# 3067M register map
File version: 1.0
Registers are 32-bit, access per field, reset 0x0 unless marked. A register's access mark holds for its fields unless they carry their own. Offsets are from the block's base; [hi:lo] are bit positions; {n}, {i} and the like mark numbered series.

## TSENSOR — TSENSOR peripheral interface
Base 0x18500000
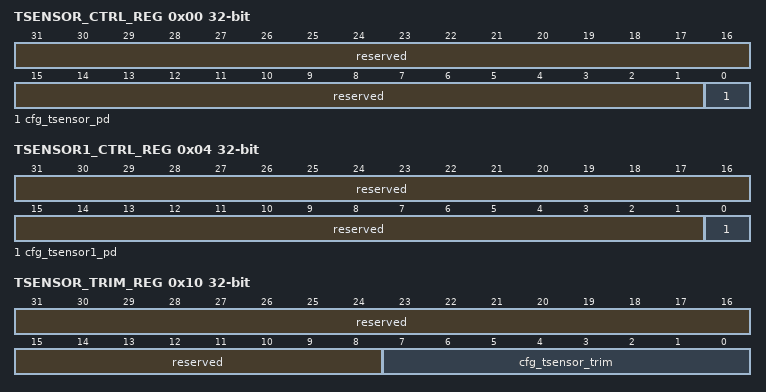
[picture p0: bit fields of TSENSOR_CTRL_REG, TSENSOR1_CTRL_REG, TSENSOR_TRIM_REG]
0x00 TSENSOR_CTRL_REG — TSENSOR控制寄存器。
  [31:1] reserved ro — 保留。
  [0] cfg_tsensor_pd rw — Tsensor0的关断信号。 0：使能Tsensor0； 1：关断Tsensor0。
0x04 TSENSOR1_CTRL_REG — TSENSOR1控制寄存器。
  [31:1] reserved ro — 保留。
  [0] cfg_tsensor1_pd rw — Tsensor1的关断信号。 0：使能Tsensor1； 1：关断Tsensor1。
0x10 TSENSOR_TRIM_REG — TSENSOR TRIM寄存器
  [31:8] reserved ro — 保留。
  [7:0] cfg_tsensor_trim rw — Tsensor0 trim信息。

## SYSCTRL0 — SYSCTRL0 peripheral interface
Base 0x10100000
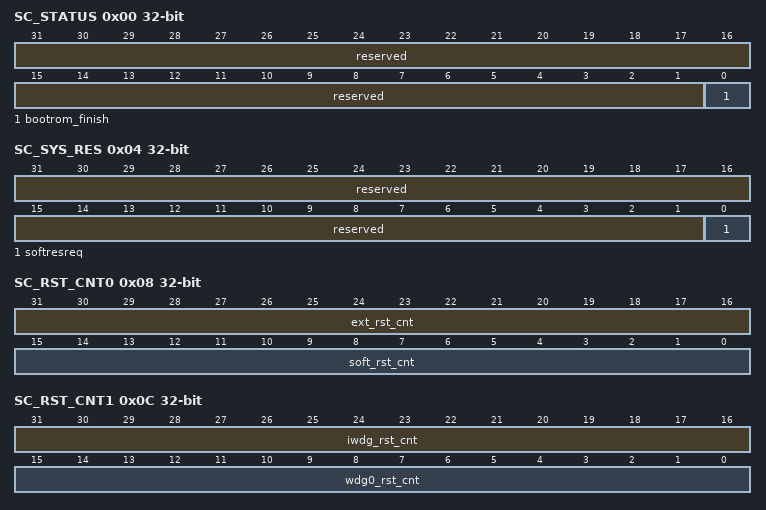
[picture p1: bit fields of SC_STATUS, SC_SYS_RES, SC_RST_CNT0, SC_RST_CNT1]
0x00 SC_STATUS access not given — SC_STATUS为系统状态寄存器。
  [31:1] reserved ro — 保留。
  [0] bootrom_finish — bootrom退出时，需将该寄存器改写为1。 注意：与OTP的bootrom_debug_enable、bootrom_hide_disable配合完成相关安全保护。
0x04 SC_SYS_RES access not given — SC_SYS_RES为系统软件复位寄存器。 该寄存器受写保护控制，由寄存器SC_LOCKEN[sc_cfg_lock]决定。只有写使能时，对此寄存器的写操作才有效。
  [31:1] reserved ro — 保留。
  [0] softresreq — 对此寄存器位域的任意写操作都会导致系统软复位。
0x08 SC_RST_CNT0 ro — SC_RST_CNT0为复位次数统计寄存器0。
  [31:16] ext_rst_cnt — RESETN管脚复位次数统计。
  [15:0] soft_rst_cnt — 软复位次数统计。
0x0C SC_RST_CNT1 ro — SC_RST_CNT1为复位次数统计寄存器1。
  [31:16] iwdg_rst_cnt — IWDG复位次数统计。
  [15:0] wdg0_rst_cnt — WDG0复位次数统计。
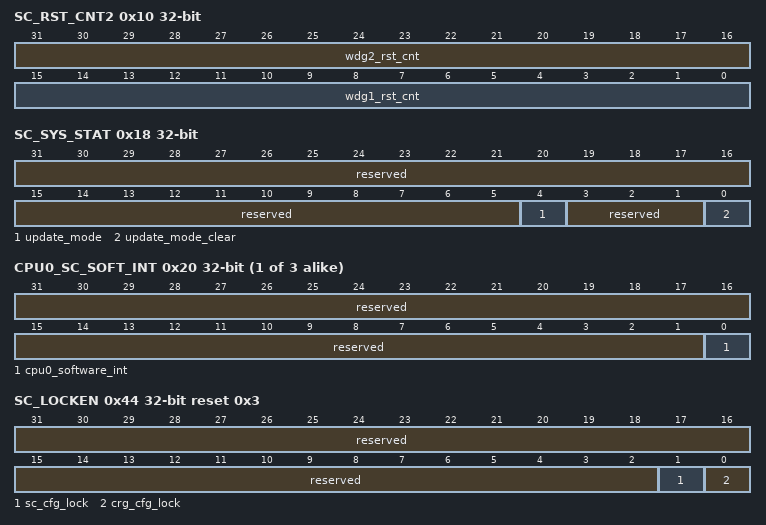
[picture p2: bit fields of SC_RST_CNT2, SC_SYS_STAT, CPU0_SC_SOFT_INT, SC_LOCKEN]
0x10 SC_RST_CNT2 ro — SC_RST_CNT2为复位次数统计寄存器2。
  [31:16] wdg2_rst_cnt — WDG2复位次数统计。
  [15:0] wdg1_rst_cnt — WDG1复位次数统计。
0x18 SC_SYS_STAT — SC_SYS_STAT为系统启动模式寄存器。
  [31:5] reserved ro — 保留。
  [4] update_mode ro — 系统升级标识，芯片上电时锁存。 0：不升级，直接启动模式； 1：升级模式。 注意：当处于升级模式时，芯片JTAG相关管脚强制为JTAG功能，无法软件切换为其他复用功能。
  [3:1] reserved ro — 保留。
  [0] update_mode_clear rw — 系统升级标识清除寄存器，芯片上电完成后生效。 0：不清除； 1：清除。
{0x20+8i} CPU{i}_SC_SOFT_INT (i=0..2) — CPU{i}_SC_SOFT_INT为CPU{i}软件中断寄存器。
  [31:1] reserved ro — 保留。
  [0] cpu{i}_software_int rw — CPU{i}软件中断寄存器。 0：清除中断； 1：产生中断。
{0x24+8i} CPU{i}_SC_SOFT_EVT_ID rw (i=0..2) — CPU{i}_SC_SOFT_EVT_ID为CPU{i}软中断事件ID寄存器。
  [31:0] cpu{i}_swint_evt_id — CPU{i}软中断事件ID，可用于软中断事件类型定义。
0x44 SC_LOCKEN reset 0x3 — SC_LOCKEN为关键寄存器的写保护控制寄存器。 仅当word写操作数的bit[31:16]位域为0xEA51时，才能对此寄存器进行写操作。
  [31:2] reserved ro — 保留。
  [1] sc_cfg_lock rw — SYSCTRL相关寄存器写保护。 0：写使能； 1：写禁止。
  [0] crg_cfg_lock rw — CRG相关寄存器写保护。 0：写使能； 1：写禁止。
{0x100+4i} SC_SYS_BOOT{i} rw (i=0..3) — SC_SYS_BOOT{i}为系统启动专用寄存器{i}。
  [31:0] sysboot{i} — 系统启动专用寄存器{i}。
0x200 SC_HRST_REG0 access not given — SC_HRST_REG0为SC专用硬复位寄存器0。 该寄存器不会被系统软件复位所复位。
  [31:0] sc_hrst_reg0 — 系统正常启动流程中，如果检测到此寄存器值为0xA5A5A5A5，则CPU将停止启动系统，此时可以通过JTAG/SWD接口调试（或烧写）。
0x204 SC_HRST_REG1 access not given — SC_HRST_REG1为SC专用硬复位寄存器1。 该寄存器不会被系统软件复位所复位。
0x240 SC_POR_REG0 access not given — SC_POR_REG0为SC专用POR复位寄存器0。 该寄存器仅被POR复位或从低功耗模式唤醒时复位。
0x244 SC_POR_REG1 access not given — SC_POR_REG1为SC专用POR复位寄存器1。 该寄存器仅被POR复位或从低功耗模式唤醒时复位。
0x280 SC_REG0 rw — SC_REG0为SC专用寄存器0。
0x284 SC_REG1 rw — SC_REG1为SC专用寄存器1。
0xE00 USER_POR_REG0 rw — USER_POR_REG0为USER专用POR复位寄存器0。 该寄存器仅被POR复位或从低功耗模式唤醒时复位。
  [31:0] user_por_reg0 — USER专用REG0。
0xE04 USER_POR_REG1 rw — USER_POR_REG1为USER专用POR复位寄存器1。 该寄存器仅被POR复位或从低功耗模式唤醒时复位。
  [31:0] user_por_reg1 — USER专用REG1。
0xE40 USER_HRST_REG0 rw — USER_HRST_REG0为USER专用硬复位寄存器0。 该寄存器不会被系统软复位所复位。
  [31:0] user_hrst_reg0 — USER专用REG2。
0xE44 USER_HRST_REG1 rw — USER_HRST_REG1为USER专用硬复位寄存器1。 该寄存器不会被系统软复位所复位。
  [31:0] user_hrst_reg1 — USER专用REG3。
0xE80 USER_REG0 rw — USER_REG0为USER专用寄存器0。
  [31:0] user_reg0 — USER专用REG4。
0xE84 USER_REG1 rw — USER_REG1为USER专用寄存器1。
  [31:0] user_reg1 — USER专用REG5。
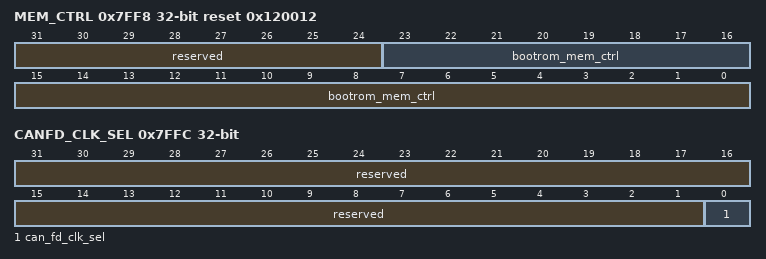
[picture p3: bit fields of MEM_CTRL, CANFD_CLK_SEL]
0x7FF8 MEM_CTRL reset 0x120012 — MEM_CTRL为系统MEMORY控制寄存器。
  [31:24] reserved ro — 保留。
  [23:16] bootrom_mem_ctrl rw — 系统MEM的配置。
  [15:0] bootrom_mem_ctrl rw — CAN的MEM配置。
0x7FFC CANFD_CLK_SEL — CANFD_CLK_SEL为CANFD的时钟选择。
  [31:1] reserved ro — 保留。
  [0] can_fd_clk_sel rw — CANFD工作钟选择寄存器。 0：canfd模块工作钟选择clk_pll_ref_ini时钟； 1：canfd模块工作时钟选择PLL1输出的时钟。

## SRM — SRM peripheral interface
Base 0x14A20000
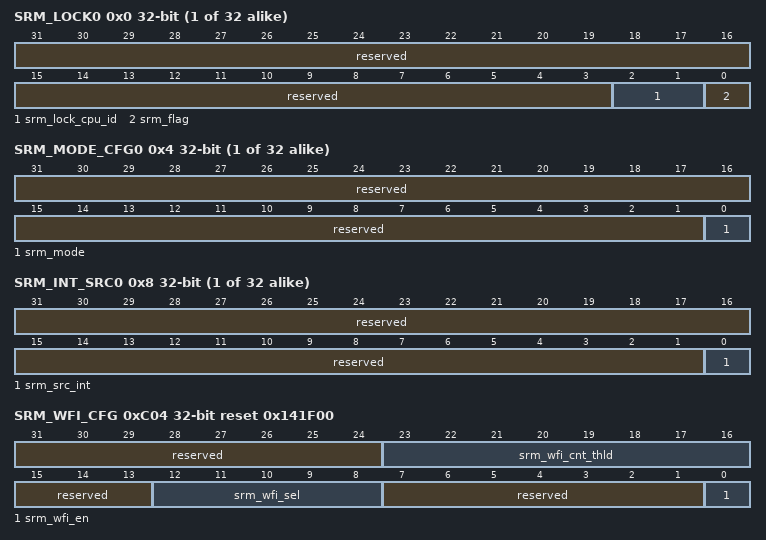
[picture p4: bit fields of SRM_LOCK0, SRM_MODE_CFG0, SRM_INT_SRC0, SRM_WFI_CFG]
{0x0+0x10*i} SRM_LOCK{i} (i=0..31) — SRM_LOCK{i}为共享资源锁定寄存器。
  [31:3] reserved ro — 保留。
  [2:1] srm_lock_cpu_id ro — 锁存此信号量的CPU_ID。 00：CPU0； 01：CPU1； 10：CPU2； 其他：无效；
  [0] srm_flag rw — 查询模式下。 写0：释放该信号量； 读占用信号量；不支持写占用该信号量。 写模式下： 读操作： 0：当前信号量空闲； 1：当前信号量被占用。 写操作： 0：释放该信号量； 1：占用该信号量。
{0x4+0x10*i} SRM_MODE_CFG{i} (i=0..31) — SRM_MODE_CFG{i}为共享资源模式寄存器。
  [31:1] reserved ro — 保留。
  [0] srm_mode rw — 工作模式。 0：查询模式； 1：写模式。
{0x8+0x10*i} SRM_INT_SRC{i} (i=0..31) — SRM_INT_SRC{i}为共享资源通道的原始中断。
  [31:1] reserved ro — 保留。
  [0] srm_src_int rw write-clears — 共享资源通道的原始中断，写1清零。 0：无中断； 1：有中断。
{0x800+0x10*i} SRM_CORE_INT_EN{i} rw (i=0..2) — SRM_CORE_INT_EN{i}为SRM上报到CPU的中断使能寄存器。
  [31:0] srm_channel_int_en — CPU核使用的共享通道的中断使能。 对应bit标识对应的SEM资源是是否上报中断到CPU核； 0：屏蔽中断； 1：不屏蔽中断。
{0x804+0x10*i} SRM_CORE_INT{i} ro (i=0..2) — SRM_CORE_INT{i}为CPU的中断状态查询寄存器。
  [31:0] srm_channel_int — CPU核使用的共享通道的中断状态。
0xC00 SRM_LOCK_STA ro — SRM_LOCK_STA为共享资源状态寄存器。
  [31:0] srm_lock_sta — SEM资源是否被锁定。 0：共享资源未被占用； 1：共享资源已占用。
0xC04 SRM_WFI_CFG reset 0x141F00 — SRM_WFI_CFG为共享资源状态寄存器。
  [31:24] reserved ro — 保留。
  [23:16] srm_wfi_cnt_thld rw — WFI错峰进入间隔时间配置，单位为系统时钟cycle，默认值为20个cycle。
  [15:13] reserved ro — 保留。
  [12:8] srm_wfi_sel rw — SRM编号0~31，选定哪个SRM旗语用作WFI错峰进入的旗语，默认选择最后一个旗语作为WFI错峰进入。
  [7:1] reserved ro — 保留。
  [0] srm_wfi_en rw — SRM_WFI_EN，支持32个SRM中任意一个SRM用做WFI进入错峰旗语，该旗语支持超时后自动释放通道占用。
